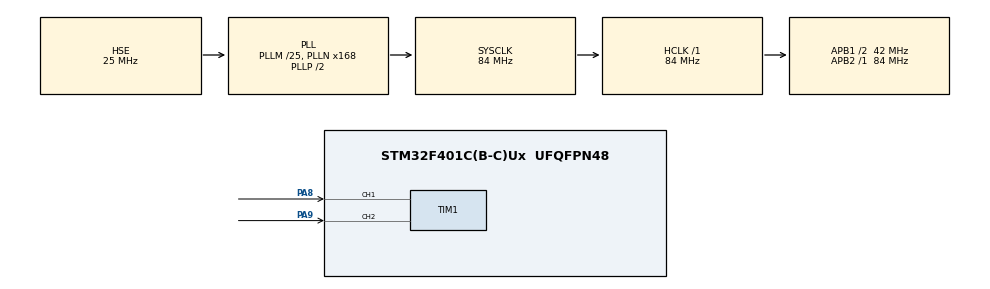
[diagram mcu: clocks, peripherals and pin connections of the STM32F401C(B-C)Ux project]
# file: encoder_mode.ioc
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Mcu.Family=STM32F4
RCC.PLLSourceVirtual=RCC_PLLSOURCE_HSE
RCC.CortexFreq_Value=84000000
PH1\ -\ OSC_OUT.Mode=HSE-External-Oscillator
Dma.TIM1_UP.0.Mode=DMA_CIRCULAR
RCC.APB1CLKDivider=RCC_HCLK_DIV2
PA9.GPIO_PuPd=GPIO_PULLUP
RCC.SYSCLKSource=RCC_SYSCLKSOURCE_PLLCLK
ProjectManager.StackSize=0x400
PA9.GPIO_ModeDefaultPP=GPIO_MODE_AF_PP
PA13.Signal=SYS_JTMS-SWDIO
Dma.TIM1_UP.0.PeriphDataAlignment=DMA_PDATAALIGN_HALFWORD
Dma.TIM1_UP.0.MemInc=DMA_MINC_ENABLE
PH0\ -\ OSC_IN.Mode=HSE-External-Oscillator
SH.S_TIM1_CH1.0=TIM1_CH1,Encoder_Interface
PH0\ -\ OSC_IN.Signal=RCC_OSC_IN
ProjectManager.TargetToolchain=STM32CubeIDE
RCC.HCLKFreq_Value=84000000
RCC.APB2TimFreq_Value=84000000
PA9.Signal=S_TIM1_CH2
Dma.TIM1_UP.0.Priority=DMA_PRIORITY_LOW
RCC.LSE_VALUE=32768
RCC.AHBFreq_Value=84000000
RCC.HSE_VALUE=25000000
PH1\ -\ OSC_OUT.Signal=RCC_OSC_OUT
board=custom
PA8.GPIO_ModeDefaultPP=GPIO_MODE_AF_PP
RCC.VCOOutputFreq_Value=168000000
Dma.TIM1_UP.0.Instance=DMA2_Stream5
RCC.APB2Freq_Value=84000000
SH.S_TIM1_CH2.0=TIM1_CH2,Encoder_Interface
PA14.Mode=Serial_Wire
NVIC.DMA2_Stream5_IRQn=true\:0\:0\:false\:false\:true\:false\:true
PA8.Signal=S_TIM1_CH1
PA13.Mode=Serial_Wire
Dma.TIM1_UP.0.PeriphInc=DMA_PINC_DISABLE
Mcu.Name=STM32F401C(B-C)Ux
RCC.48MHZClocksFreq_Value=42000000
RCC.SYSCLKFreq_VALUE=84000000
Mcu.Package=UFQFPN48
Dma.TIM1_UP.0.Direction=DMA_PERIPH_TO_MEMORY
PA14.Signal=SYS_JTCK-SWCLK
ProjectManager.HeapSize=0x200
Dma.TIM1_UP.0.MemDataAlignment=DMA_MDATAALIGN_HALFWORD
RCC.HSI_VALUE=16000000
PA8.GPIO_PuPd=GPIO_PULLUP
NVIC.PriorityGroup=NVIC_PRIORITYGROUP_4
RCC.PLLM=25
RCC.PLLN=168
RCC.APB1TimFreq_Value=84000000
PA9.GPIO_Speed=GPIO_SPEED_FREQ_LOW
RCC.APB1Freq_Value=42000000
Dma.Request0=TIM1_UP
PA8.GPIO_Speed=GPIO_SPEED_FREQ_LOW
Dma.TIM1_UP.0.FIFOMode=DMA_FIFOMODE_DISABLE

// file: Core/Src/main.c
/* USER CODE BEGIN Header */
/**
  ******************************************************************************
  * @file           : main.c
  * @brief          : Main program body
  ******************************************************************************
  * @attention
  *
  * <h2><center>&copy; Copyright (c) 2021 STMicroelectronics.
  * All rights reserved.</center></h2>
  *
  * This software component is licensed by ST under BSD 3-Clause license,
  * the "License"; You may not use this file except in compliance with the
  * License. You may obtain a copy of the License at:
  *                        opensource.org/licenses/BSD-3-Clause
  *
  ******************************************************************************
  */
/* USER CODE END Header */
#include "main.h"

TIM_HandleTypeDef htim1;
DMA_HandleTypeDef hdma_tim1_up;

/* USER CODE BEGIN PV */
int16_t konter=0;
uint8_t dir=0;
uint32_t datasatu,datadua;
/* USER CODE END PV */

void SystemClock_Config(void);
static void MX_GPIO_Init(void);
static void MX_DMA_Init(void);
static void MX_TIM1_Init(void);

int main(void)
{

  /* MCU Configuration--------------------------------------------------------*/

  /* Reset of all peripherals, Initializes the Flash interface and the Systick. */
  HAL_Init();

  /* Configure the system clock */
  SystemClock_Config();

  /* Initialize all configured peripherals */
  MX_GPIO_Init();
  MX_DMA_Init();
  MX_TIM1_Init();
  /* USER CODE BEGIN 2 */
  HAL_TIM_Encoder_Start_DMA(&htim1, TIM_CHANNEL_ALL, (uint32_t*)datasatu, (uint32_t*)datadua, 1);
  //HAL_TIM_Encoder_Start(&htim1,TIM_CHANNEL_ALL);
  /* USER CODE END 2 */

  /* Infinite loop */
  while (1)
  {

    /* USER CODE BEGIN 3 */
	  konter = htim1.Instance->CNT;
	  dir = __HAL_TIM_IS_TIM_COUNTING_DOWN(&htim1);

  }
  /* USER CODE END 3 */
}

void SystemClock_Config(void)
{
  RCC_OscInitTypeDef RCC_OscInitStruct = {0};
  RCC_ClkInitTypeDef RCC_ClkInitStruct = {0};

  /** Configure the main internal regulator output voltage
  */
  __HAL_RCC_PWR_CLK_ENABLE();
  __HAL_PWR_VOLTAGESCALING_CONFIG(PWR_REGULATOR_VOLTAGE_SCALE2);
  /** Initializes the RCC Oscillators according to the specified parameters
  * in the RCC_OscInitTypeDef structure.
  */
  RCC_OscInitStruct.OscillatorType = RCC_OSCILLATORTYPE_HSE;
  RCC_OscInitStruct.HSEState = RCC_HSE_ON;
  RCC_OscInitStruct.PLL.PLLState = RCC_PLL_ON;
  RCC_OscInitStruct.PLL.PLLSource = RCC_PLLSOURCE_HSE;
  RCC_OscInitStruct.PLL.PLLM = 25;
  RCC_OscInitStruct.PLL.PLLN = 168;
  RCC_OscInitStruct.PLL.PLLP = RCC_PLLP_DIV2;
  RCC_OscInitStruct.PLL.PLLQ = 4;
  if (HAL_RCC_OscConfig(&RCC_OscInitStruct) != HAL_OK)
  {
    Error_Handler();
  }
  /** Initializes the CPU, AHB and APB buses clocks
  */
  RCC_ClkInitStruct.ClockType = RCC_CLOCKTYPE_HCLK|RCC_CLOCKTYPE_SYSCLK
                              |RCC_CLOCKTYPE_PCLK1|RCC_CLOCKTYPE_PCLK2;
  RCC_ClkInitStruct.SYSCLKSource = RCC_SYSCLKSOURCE_PLLCLK;
  RCC_ClkInitStruct.AHBCLKDivider = RCC_SYSCLK_DIV1;
  RCC_ClkInitStruct.APB1CLKDivider = RCC_HCLK_DIV2;
  RCC_ClkInitStruct.APB2CLKDivider = RCC_HCLK_DIV1;

  if (HAL_RCC_ClockConfig(&RCC_ClkInitStruct, FLASH_LATENCY_2) != HAL_OK)
  {
    Error_Handler();
  }
}

static void MX_TIM1_Init(void)
{

  TIM_Encoder_InitTypeDef sConfig = {0};
  TIM_MasterConfigTypeDef sMasterConfig = {0};

  htim1.Instance = TIM1;
  htim1.Init.Prescaler = 0;
  htim1.Init.CounterMode = TIM_COUNTERMODE_UP;
  htim1.Init.Period = 65535;
  htim1.Init.ClockDivision = TIM_CLOCKDIVISION_DIV1;
  htim1.Init.RepetitionCounter = 0;
  htim1.Init.AutoReloadPreload = TIM_AUTORELOAD_PRELOAD_DISABLE;
  sConfig.EncoderMode = TIM_ENCODERMODE_TI1;
  sConfig.IC1Polarity = TIM_ICPOLARITY_RISING;
  sConfig.IC1Selection = TIM_ICSELECTION_DIRECTTI;
  sConfig.IC1Prescaler = TIM_ICPSC_DIV1;
  sConfig.IC1Filter = 0;
  sConfig.IC2Polarity = TIM_ICPOLARITY_RISING;
  sConfig.IC2Selection = TIM_ICSELECTION_DIRECTTI;
  sConfig.IC2Prescaler = TIM_ICPSC_DIV1;
  sConfig.IC2Filter = 0;
  if (HAL_TIM_Encoder_Init(&htim1, &sConfig) != HAL_OK)
  {
    Error_Handler();
  }
  sMasterConfig.MasterOutputTrigger = TIM_TRGO_RESET;
  sMasterConfig.MasterSlaveMode = TIM_MASTERSLAVEMODE_DISABLE;
  if (HAL_TIMEx_MasterConfigSynchronization(&htim1, &sMasterConfig) != HAL_OK)
  {
    Error_Handler();
  }

}

static void MX_DMA_Init(void)
{

  /* DMA controller clock enable */
  __HAL_RCC_DMA2_CLK_ENABLE();

  /* DMA interrupt init */
  /* DMA2_Stream5_IRQn interrupt configuration */
  HAL_NVIC_SetPriority(DMA2_Stream5_IRQn, 0, 0);
  HAL_NVIC_EnableIRQ(DMA2_Stream5_IRQn);

}

static void MX_GPIO_Init(void)
{

  /* GPIO Ports Clock Enable */
  __HAL_RCC_GPIOH_CLK_ENABLE();
  __HAL_RCC_GPIOA_CLK_ENABLE();

}

void Error_Handler(void)
{
  __disable_irq();
  while (1)
  {
  }
}

/************************ (C) COPYRIGHT STMicroelectronics *****END OF FILE****/
